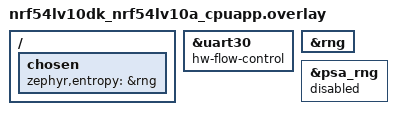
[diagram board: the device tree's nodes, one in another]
/*
 * Copyright (c) 2025 Nordic Semiconductor ASA
 *
 * SPDX-License-Identifier: LicenseRef-Nordic-5-Clause
 */

&uart30 {
	hw-flow-control;
};

/ {
	chosen {
		zephyr,entropy = &rng;
	};
};

&rng {
	status = "okay";
};

&psa_rng {
	status = "disabled";
};
